# MCXA153 register map
Vendor: nxp.com; File version: 1.0
CPU: CM33 r2p0, little endian, no MPU, no FPU, VTOR, 3 interrupt priority bits
Registers are 32-bit, read-write, reset 0x0 unless marked. A register's access mark holds for its fields unless they carry their own. Offsets are from the block's base; [hi:lo] are bit positions; lines under a group give offsets from that group; {n}, {i} and the like mark numbered series.

## VBAT0 — VBAT
Base 0x40093000
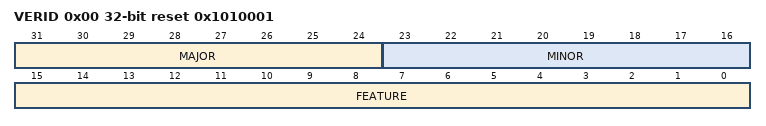
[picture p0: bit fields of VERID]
0x00 VERID ro reset 0x1010001 — Version ID
  [31:24] MAJOR — Major Version Number
  [23:16] MINOR — Minor Version Number
  [15:0] FEATURE — Feature Specification Number
0x200 FROCTLA reset 0x1 — FRO16K Control A
  [0] FRO_EN — FRO16K Enable
    0=DISABLE; 1=ENABLE
0x218 FROLCKA — FRO16K Lock A
  [0] LOCK
    0=DISABLE (Do not block); 1=ENABLE (Block)
0x220 FROCLKE — FRO16K Clock Enable
  [1:0] CLKE — Clock Enable
{0x700+8i} WAKEUP[{i}] (i=0..1) group — Array of registers: WAKEUPA
  0x00 WAKEUPA — Wakeup 0 Register A
    [31:0] REG — Register
0x7F8 WAKLCKA — Wakeup Lock A
  [0] LOCK
    0=DISABLE (Lock is disabled); 1=ENABLE (Lock is enabled)

## FMC0 — NPX
Base 0x40094000
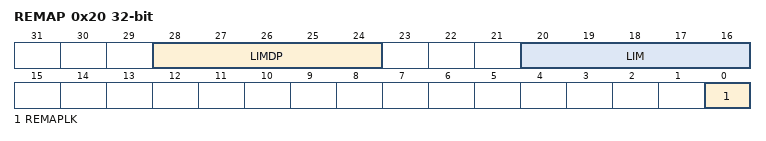
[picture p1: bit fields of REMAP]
0x20 REMAP — Data Remap
  [28:24] LIMDP — LIMDP Remapping Address
  [20:16] LIM — LIM Remapping Address
  [0] REMAPLK — Remap Lock Enable
    0=LOCK_DISABLED (Lock disabled: can write to REMAP); 1=LOCK_ENABLED (Lock enabled: cannot write to REMAP)

## LPTMR0 — LPTMR
Base 0x400AB000
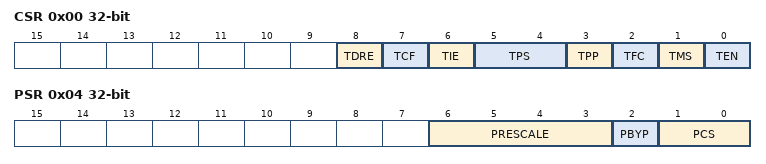
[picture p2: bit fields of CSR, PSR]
0x00 CSR — Control Status
  [8] TDRE — Timer DMA Request Enable
    0=trde0 (Disable); 1=trde1 (Enable)
  [7] TCF write-1-clears — Timer Compare Flag
    on read: 0=CNR != (CMR + 1); 1=CNR = (CMR + 1)
  [6] TIE — Timer Interrupt Enable
    0=Disable; 1=Enable
  [5:4] TPS — Timer Pin Select
    {v}=Input {v} (v=0..3)
  [3] TPP — Timer Pin Polarity
    0=Active-high; 1=Active-low
  [2] TFC — Timer Free-Running Counter
    0=Reset when TCF asserts; 1=Reset on overflow
  [1] TMS — Timer Mode Select
    0=Time Counter; 1=Pulse Counter
  [0] TEN — Timer Enable
    0=Disable; 1=Enable
0x04 PSR — Prescaler and Glitch Filter
  [6:3] PRESCALE — Prescaler and Glitch Filter Value
    0=Prescaler divides the prescaler clock by 2; glitch filter does not support this configuration; 1=Prescaler divides the prescaler clock by 4; glitch filter recognizes change on input pin after two rising clock edges; 2=Prescaler divides the prescaler clock by 8; glitch filter recognizes change on input pin after four rising clock edges; 3=Prescaler divides the prescaler clock by 16; glitch filter recognizes change on input pin after eight rising clock edges; 4=Prescaler divides the prescaler clock by 32; glitch filter recognizes change on input pin after 16 rising clock edges; 5=Prescaler divides the prescaler clock by 64; glitch filter recognizes change on input pin after 32 rising clock edges; 6=Prescaler divides the prescaler clock by 128; glitch filter recognizes change on input pin after 64 rising clock edges; 7=Prescaler divides the prescaler clock by 256; glitch filter recognizes change on input pin after 128 rising clock edges; 8=Prescaler divides the prescaler clock by 512; glitch filter recognizes change on input pin after 256 rising clock edges; 9=Prescaler divides the prescaler clock by 1024; glitch filter recognizes change on input pin after 512 rising clock edges; 10=Prescaler divides the prescaler clock by 2048; glitch filter recognizes change on input pin after 1024 rising clock edges; 11=Prescaler divides the prescaler clock by 4096; glitch filter recognizes change on input pin after 2048 rising clock edges; 12=Prescaler divides the prescaler clock by 8192; glitch filter recognizes change on input pin after 4096 rising clock edges; 13=Prescaler divides the prescaler clock by 16,384; glitch filter recognizes change on input pin after 8192 rising clock edges; 14=Prescaler divides the prescaler clock by 32,768; glitch filter recognizes change on input pin after 16,384 rising clock edges; 15=Prescaler divides the prescaler clock by 65,536; glitch filter recognizes change on input pin after 32,768 rising clock edges
  [2] PBYP — Prescaler and Glitch Filter Bypass
    0=Prescaler and glitch filter enable; 1=Prescaler and glitch filter bypass
  [1:0] PCS — Prescaler and Glitch Filter Clock Select
    {v}=Clock {v} (v=0..3)
0x08 CMR — Compare
  [31:0] COMPARE — Compare Value
0x0C CNR — Counter
  [31:0] COUNTER — Counter Value
